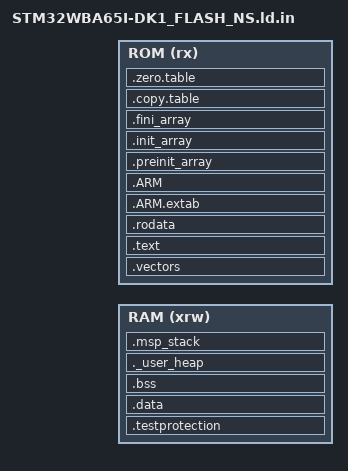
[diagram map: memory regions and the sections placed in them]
/*
******************************************************************************
**
** @file        : STM32WBA65I-DK1_FLASH_NS.ld
**
** @brief       : Linker script for STM32WBA65I-DK1 OEMiROT NonSecure build
**                This file uses preprocessor includes - must be processed
**                with arm-none-eabi-gcc -E -P before linking
**
******************************************************************************
*/
#include "appli_region_defs.h"

/* Entry Point */
ENTRY(Reset_Handler)

/* Highest address of the user mode stack */
_estack = ORIGIN(RAM) + LENGTH(RAM); /* end of "RAM" Ram type memory */

_Min_Heap_Size = NS_HEAP_SIZE ; /* required amount of heap  */
_Min_Stack_Size = NS_C_STACK_SIZE ; /* required amount of stack */

/* Memories definition */
MEMORY
{
  RAM (xrw) : ORIGIN = NS_RAM_START, LENGTH = NS_RAM_SIZE
  ROM (rx)  : ORIGIN = NS_CODE_START, LENGTH = NS_CODE_SIZE
}

/* Sections */
SECTIONS
{
  /* The startup code into "ROM" Rom type memory */
  .vectors :
  {
    . = ALIGN(8);
    KEEP(*(.vectors)) /* Startup code */
    . = ALIGN(8);
  } >ROM

  /* The program code and other data into "ROM" Rom type memory */
  .text :
  {
    . = ALIGN(8);
    *(.text)           /* .text sections (code) */
    *(.text*)          /* .text* sections (code) */
    *(.glue_7)         /* glue arm to thumb code */
    *(.glue_7t)        /* glue thumb to arm code */
    *(.eh_frame)

    KEEP (*(.init))
    KEEP (*(.fini))

    . = ALIGN(8);
    _etext = .;        /* define a global symbols at end of code */
  } >ROM

  /* Constant data into "ROM" Rom type memory */
  .rodata :
  {
    . = ALIGN(8);
    *(.rodata)         /* .rodata sections (constants, strings, etc.) */
    *(.rodata*)        /* .rodata* sections (constants, strings, etc.) */
    . = ALIGN(8);
  } >ROM

  .ARM.extab (READONLY) :
  {
    . = ALIGN(8);
    *(.ARM.extab* .gnu.linkonce.armextab.*)
    . = ALIGN(8);
  } >ROM

  .ARM (READONLY) :
  {
    . = ALIGN(8);
    __exidx_start = .;
    *(.ARM.exidx*)
    __exidx_end = .;
    . = ALIGN(8);
  } >ROM

  .preinit_array (READONLY) :
  {
    . = ALIGN(8);
    PROVIDE_HIDDEN (__preinit_array_start = .);
    KEEP (*(.preinit_array*))
    PROVIDE_HIDDEN (__preinit_array_end = .);
    . = ALIGN(8);
  } >ROM

  .init_array (READONLY) :
  {
    . = ALIGN(8);
    PROVIDE_HIDDEN (__init_array_start = .);
    KEEP (*(SORT(.init_array.*)))
    KEEP (*(.init_array*))
    PROVIDE_HIDDEN (__init_array_end = .);
    . = ALIGN(8);
  } >ROM

  .fini_array (READONLY) :
  {
    . = ALIGN(8);
    PROVIDE_HIDDEN (__fini_array_start = .);
    KEEP (*(SORT(.fini_array.*)))
    KEEP (*(.fini_array*))
    PROVIDE_HIDDEN (__fini_array_end = .);
    . = ALIGN(8);
  } >ROM

  .copy.table (READONLY) :
  {
    . = ALIGN(4);
    __copy_table_start__ = .;
    LONG (__etext)
    LONG (_sdata)
    LONG ((_edata - _sdata)/4)
    __copy_table_end__ = .;
  } > ROM

  .zero.table (READONLY) :
  {
    . = ALIGN(4);
    __zero_table_start__ = .;
    LONG (__bss_start__)
    LONG ((__bss_end__ - __bss_start__)/4)
    __zero_table_end__ = .;
   } > ROM
   __etext = .;

  .testprotection NS_RAM_START :
  {
         *(.bss.NoInit);
  } > RAM

  .data (NS_RAM_START + RAM_NS_NO_INIT_SIZE) : AT (__etext)
  {
    . = ALIGN(8);
    _sdata = .;        /* create a global symbol at data start */
    *(.data)           /* .data sections */
    *(.data*)          /* .data* sections */

    . = ALIGN(8);
    _edata = .;        /* define a global symbol at data end */

  } >RAM

  /* Uninitialized data section into "RAM" Ram type memory */
  . = ALIGN(8);
  .bss :
  {
    /* This is used by the startup in order to initialize the .bss section */
    _sbss = .;         /* define a global symbol at bss start */
    __bss_start__ = _sbss;
    *(.bss)
    *(.bss*)
    *(COMMON)

    . = ALIGN(8);
    _ebss = .;         /* define a global symbol at bss end */
    __bss_end__ = _ebss;
  } >RAM

  /* User_heap_stack section, used to check that there is enough "RAM" Ram  type memory left */
  ._user_heap :
  {
    . = ALIGN(8);
    PROVIDE ( end = . );
    PROVIDE ( _end = . );
    . = . + _Min_Heap_Size;
    . = ALIGN(8);
  } >RAM

  .msp_stack :
  {
    . = ALIGN(8);
    . += _Min_Stack_Size;
  } > RAM
  Image$$ARM_LIB_STACK$$ZI$$Limit = ADDR(.msp_stack) + SIZEOF(.msp_stack);
  Image$$ARM_LIB_STACK$$ZI$$Base = ADDR(.msp_stack) ;

  /* Remove information from the compiler libraries */
  /DISCARD/ :
  {
    libc.a ( * )
    libm.a ( * )
    libgcc.a ( * )
  }

  .ARM.attributes 0 : { *(.ARM.attributes) }
  PROVIDE(__stack = Image$$ARM_LIB_STACK$$ZI$$Limit);
  PROVIDE(__StackTop = Image$$ARM_LIB_STACK$$ZI$$Limit);
  PROVIDE(__StackLimit = Image$$ARM_LIB_STACK$$ZI$$Base);
}
